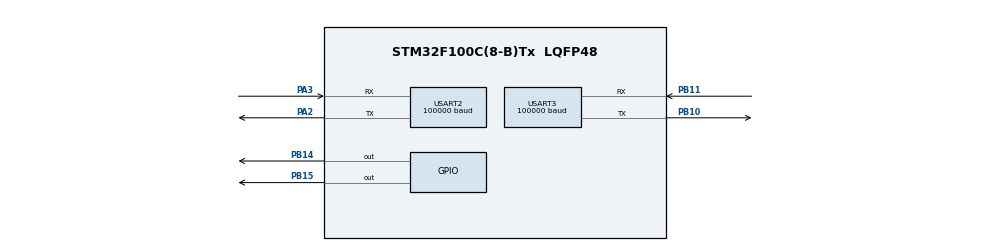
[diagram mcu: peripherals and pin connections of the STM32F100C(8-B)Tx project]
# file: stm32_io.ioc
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Mcu.Family=STM32F1
Mcu.Name=STM32F100C(8-B)Tx
Mcu.Package=LQFP48
NVIC.PriorityGroup=NVIC_PRIORITYGROUP_4
NVIC.USART3_IRQn=true\:0\:0\:false\:false\:true\:true\:true\:true
PA13.Mode=Serial_Wire
PA13.Signal=SYS_JTMS-SWDIO
PA14.Mode=Serial_Wire
PA14.Signal=SYS_JTCK-SWCLK
PA2.Mode=Asynchronous
PA2.Signal=USART2_TX
PA3.Mode=Asynchronous
PA3.Signal=USART2_RX
PB10.Mode=Asynchronous
PB10.Signal=USART3_TX
PB11.Mode=Asynchronous
PB11.Signal=USART3_RX
PB14.Signal=GPIO_Output
PB15.Signal=GPIO_Output
PD0-OSC_IN.Mode=HSE-External-Oscillator
PD0-OSC_IN.Signal=RCC_OSC_IN
PD1-OSC_OUT.Mode=HSE-External-Oscillator
PD1-OSC_OUT.Signal=RCC_OSC_OUT
ProjectManager.HeapSize=0x200
ProjectManager.StackSize=0x400
ProjectManager.TargetToolchain=TrueSTUDIO
RCC.AHBFreq_Value=24000000
RCC.APB1Freq_Value=24000000
RCC.APB1TimFreq_Value=24000000
RCC.APB2Freq_Value=24000000
RCC.APB2TimFreq_Value=24000000
RCC.HCLKFreq_Value=24000000
RCC.HSE_VALUE=24000000
RCC.SYSCLKFreq_VALUE=24000000
RCC.SYSCLKSource=RCC_SYSCLKSOURCE_HSE
USART2.BaudRate=100000
USART2.Parity=PARITY_EVEN
USART2.StopBits=STOPBITS_2
USART2.VirtualMode=VM_ASYNC
USART2.WordLength=WORDLENGTH_9B
USART3.BaudRate=100000
USART3.Mode=MODE_RX
USART3.Parity=PARITY_EVEN
USART3.StopBits=STOPBITS_2
USART3.VirtualMode=VM_ASYNC
USART3.WordLength=WORDLENGTH_9B
board=custom

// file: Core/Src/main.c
/* USER CODE BEGIN Header */
/**
 ******************************************************************************
 * @file           : main.c
 * @brief          : Main program body
 ******************************************************************************
 * @attention
 *
 * Copyright (c) 2022 STMicroelectronics.
 * All rights reserved.
 *
 * This software is licensed under terms that can be found in the LICENSE file
 * in the root directory of this software component.
 * If no LICENSE file comes with this software, it is provided AS-IS.
 *
 ******************************************************************************
 */
/* USER CODE END Header */
#include "main.h"

void SystemClock_Config(void);
static void MX_GPIO_Init(void);
static void MX_USART2_UART_Init(void);
static void MX_USART3_UART_Init(void);

int main(void) {

	/* MCU Configuration--------------------------------------------------------*/

	/* Reset of all peripherals, Initializes the Flash interface and the Systick. */

	LL_APB2_GRP1_EnableClock(LL_APB2_GRP1_PERIPH_AFIO);
	LL_APB1_GRP1_EnableClock(LL_APB1_GRP1_PERIPH_PWR);

	NVIC_SetPriorityGrouping(NVIC_PRIORITYGROUP_4);

	/* System interrupt init*/
	/* SysTick_IRQn interrupt configuration */
	NVIC_SetPriority(SysTick_IRQn,
			NVIC_EncodePriority(NVIC_GetPriorityGrouping(), 15, 0));

	/** NOJTAG: JTAG-DP Disabled and SW-DP Enabled
	 */
	LL_GPIO_AF_Remap_SWJ_NOJTAG();

	/* Configure the system clock */
	SystemClock_Config();

	/* Initialize all configured peripherals */
	MX_GPIO_Init();
	MX_USART2_UART_Init();
	MX_USART3_UART_Init();
	/* USER CODE BEGIN 2 */
	LL_USART_EnableIT_RXNE(USART3);
	/* USER CODE END 2 */

	/* Infinite loop */
	while (1) {

	}
}

void SystemClock_Config(void) {
	LL_RCC_HSE_Enable();

	/* Wait till HSE is ready */
	while (LL_RCC_HSE_IsReady() != 1) {

	}
	LL_RCC_SetAHBPrescaler(LL_RCC_SYSCLK_DIV_1);
	LL_RCC_SetAPB1Prescaler(LL_RCC_APB1_DIV_1);
	LL_RCC_SetAPB2Prescaler(LL_RCC_APB2_DIV_1);
	LL_RCC_SetSysClkSource(LL_RCC_SYS_CLKSOURCE_HSE);

	/* Wait till System clock is ready */
	while (LL_RCC_GetSysClkSource() != LL_RCC_SYS_CLKSOURCE_STATUS_HSE) {

	}
	LL_Init1msTick(24000000);
	LL_SetSystemCoreClock(24000000);
}

static void MX_USART2_UART_Init(void) {

	LL_USART_InitTypeDef USART_InitStruct = { 0 };

	LL_GPIO_InitTypeDef GPIO_InitStruct = { 0 };

	/* Peripheral clock enable */
	LL_APB1_GRP1_EnableClock(LL_APB1_GRP1_PERIPH_USART2);

	LL_APB2_GRP1_EnableClock(LL_APB2_GRP1_PERIPH_GPIOA);
	/**USART2 GPIO Configuration
	 PA2   ------> USART2_TX
	 PA3   ------> USART2_RX
	 */
	GPIO_InitStruct.Pin = LL_GPIO_PIN_2;
	GPIO_InitStruct.Mode = LL_GPIO_MODE_ALTERNATE;
	GPIO_InitStruct.Speed = LL_GPIO_SPEED_FREQ_HIGH;
	GPIO_InitStruct.OutputType = LL_GPIO_OUTPUT_PUSHPULL;
	LL_GPIO_Init(GPIOA, &GPIO_InitStruct);

	GPIO_InitStruct.Pin = LL_GPIO_PIN_3;
	GPIO_InitStruct.Mode = LL_GPIO_MODE_FLOATING;
	LL_GPIO_Init(GPIOA, &GPIO_InitStruct);

	USART_InitStruct.BaudRate = 100000;
	USART_InitStruct.DataWidth = LL_USART_DATAWIDTH_9B;
	USART_InitStruct.StopBits = LL_USART_STOPBITS_2;
	USART_InitStruct.Parity = LL_USART_PARITY_EVEN;
	USART_InitStruct.TransferDirection = LL_USART_DIRECTION_TX_RX;
	USART_InitStruct.HardwareFlowControl = LL_USART_HWCONTROL_NONE;
	USART_InitStruct.OverSampling = LL_USART_OVERSAMPLING_16;
	LL_USART_Init(USART2, &USART_InitStruct);
	LL_USART_ConfigAsyncMode(USART2);
	LL_USART_Enable(USART2);

}

static void MX_USART3_UART_Init(void) {

	LL_USART_InitTypeDef USART_InitStruct = { 0 };

	LL_GPIO_InitTypeDef GPIO_InitStruct = { 0 };

	/* Peripheral clock enable */
	LL_APB1_GRP1_EnableClock(LL_APB1_GRP1_PERIPH_USART3);

	LL_APB2_GRP1_EnableClock(LL_APB2_GRP1_PERIPH_GPIOB);
	/**USART3 GPIO Configuration
	 PB10   ------> USART3_TX
	 PB11   ------> USART3_RX
	 */
	GPIO_InitStruct.Pin = LL_GPIO_PIN_10;
	GPIO_InitStruct.Mode = LL_GPIO_MODE_ALTERNATE;
	GPIO_InitStruct.Speed = LL_GPIO_SPEED_FREQ_HIGH;
	GPIO_InitStruct.OutputType = LL_GPIO_OUTPUT_PUSHPULL;
	LL_GPIO_Init(GPIOB, &GPIO_InitStruct);

	GPIO_InitStruct.Pin = LL_GPIO_PIN_11;
	GPIO_InitStruct.Mode = LL_GPIO_MODE_FLOATING;
	LL_GPIO_Init(GPIOB, &GPIO_InitStruct);

	/* USART3 interrupt Init */
	NVIC_SetPriority(USART3_IRQn,
			NVIC_EncodePriority(NVIC_GetPriorityGrouping(), 0, 0));
	NVIC_EnableIRQ(USART3_IRQn);

	USART_InitStruct.BaudRate = 100000;
	USART_InitStruct.DataWidth = LL_USART_DATAWIDTH_9B;
	USART_InitStruct.StopBits = LL_USART_STOPBITS_2;
	USART_InitStruct.Parity = LL_USART_PARITY_EVEN;
	USART_InitStruct.TransferDirection = LL_USART_DIRECTION_RX;
	USART_InitStruct.HardwareFlowControl = LL_USART_HWCONTROL_NONE;
	USART_InitStruct.OverSampling = LL_USART_OVERSAMPLING_16;
	LL_USART_Init(USART3, &USART_InitStruct);
	LL_USART_ConfigAsyncMode(USART3);
	LL_USART_Enable(USART3);

}

static void MX_GPIO_Init(void) {
	LL_GPIO_InitTypeDef GPIO_InitStruct = { 0 };

	/* GPIO Ports Clock Enable */
	LL_APB2_GRP1_EnableClock(LL_APB2_GRP1_PERIPH_GPIOD);
	LL_APB2_GRP1_EnableClock(LL_APB2_GRP1_PERIPH_GPIOA);
	LL_APB2_GRP1_EnableClock(LL_APB2_GRP1_PERIPH_GPIOB);

	/**/
	LL_GPIO_ResetOutputPin(GPIOB, LL_GPIO_PIN_14 | LL_GPIO_PIN_15);

	/**/
	GPIO_InitStruct.Pin = LL_GPIO_PIN_14 | LL_GPIO_PIN_15;
	GPIO_InitStruct.Mode = LL_GPIO_MODE_OUTPUT;
	GPIO_InitStruct.Speed = LL_GPIO_SPEED_FREQ_LOW;
	GPIO_InitStruct.OutputType = LL_GPIO_OUTPUT_PUSHPULL;
	LL_GPIO_Init(GPIOB, &GPIO_InitStruct);

}

void Error_Handler(void) {
	__disable_irq();
	while (1) {
	}
}
